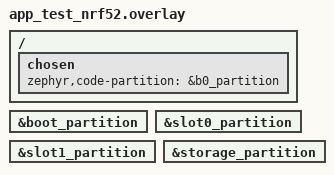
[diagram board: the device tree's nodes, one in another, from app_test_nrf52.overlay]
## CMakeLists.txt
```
#
# Copyright (c) 2019 Nordic Semiconductor ASA
#
# SPDX-License-Identifier: LicenseRef-Nordic-5-Clause
#

cmake_minimum_required(VERSION 3.20.0)

find_package(Zephyr REQUIRED HINTS $ENV{ZEPHYR_BASE})
project(bootloader)

zephyr_library_sources(src/main.c)

zephyr_compile_options("-include${CMAKE_CURRENT_LIST_DIR}/include//bl_partitions_dummy.h")
```

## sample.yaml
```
sample:
  name: Bootloader Sample
tests:
  sample.bootloader:
    sysbuild: true
    build_only: true
    integration_platforms:
      - nrf9160dk/nrf9160
      - nrf9161dk/nrf9161
      - nrf9151dk/nrf9151
      - nrf54l15dk/nrf54l15/cpuapp
    platform_allow:
      - nrf5340dk/nrf5340/cpuapp
      - nrf9160dk/nrf9160
      - nrf9161dk/nrf9161
      - nrf9151dk/nrf9151
      - nrf54l15dk/nrf54l15/cpuapp
    extra_args:
      - DTC_OVERLAY_FILE="app_test.overlay"
    tags:
      - ci_build
      - sysbuild
      - ci_samples_bootloader
```

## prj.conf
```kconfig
#
# Copyright (c) 2019 Nordic Semiconductor ASA
#
# SPDX-License-Identifier: LicenseRef-Nordic-5-Clause
#
CONFIG_IS_SECURE_BOOTLOADER=y
CONFIG_MULTITHREADING=n
CONFIG_GPIO=n
CONFIG_ARM_MPU=n
CONFIG_TICKLESS_KERNEL=n
CONFIG_ERRNO=n
CONFIG_FPROTECT=n
CONFIG_SECURE_BOOT_CRYPTO=y
CONFIG_LOG=y
CONFIG_LOG_MODE_MINIMAL=y
CONFIG_LOG_DEFAULT_LEVEL=0
CONFIG_SECURE_BOOT_VALIDATION=y
CONFIG_SECURE_BOOT_VALIDATION_LOG_LEVEL_INF=y
CONFIG_SECURE_BOOT_STORAGE=y
CONFIG_MAIN_STACK_SIZE=2048
CONFIG_TIMEOUT_64BIT=n

# Disable asserts because of false positive when writing to OTP.
CONFIG_ASSERT=n

# Avoid triggering IRQs from the RTC
CONFIG_NRF_RTC_TIMER=n
```

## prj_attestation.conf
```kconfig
# For TF-M to support attestation, NSIB must enable the mandatory IAT
# claim "implementation ID"
CONFIG_SB_IMPLEMENTATION_ID=y
```

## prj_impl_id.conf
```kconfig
# If Implementation Id is enabled in the parent image then it is supposed to be
# enabled in the b0 Child images as well
CONFIG_SB_IMPLEMENTATION_ID=y
```

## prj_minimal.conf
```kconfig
#
# Copyright (c) 2021 Nordic Semiconductor ASA
#
# SPDX-License-Identifier: LicenseRef-Nordic-5-Clause
#

CONFIG_B0_MIN_PARTITION_SIZE=y
CONFIG_FPROTECT=y
CONFIG_FW_INFO=y
CONFIG_IS_SECURE_BOOTLOADER=y
CONFIG_SECURE_BOOT_CRYPTO=y
CONFIG_SECURE_BOOT_STORAGE=y
CONFIG_SECURE_BOOT_VALIDATION=y
CONFIG_USE_DT_CODE_PARTITION=y

CONFIG_ARM_MPU=n
CONFIG_ASSERT=n
CONFIG_BOOT_BANNER=n
CONFIG_CONSOLE=n
CONFIG_ERRNO=n
CONFIG_GEN_IRQ_VECTOR_TABLE=n
CONFIG_GPIO=n
CONFIG_KERNEL_MEM_POOL=n
CONFIG_LOG=n
CONFIG_MULTITHREADING=n
CONFIG_NCS_SAMPLES_DEFAULTS=n
CONFIG_NRF_ENABLE_ICACHE=n
CONFIG_PRINTK=n
CONFIG_NCS_BOOT_BANNER=n
CONFIG_RESET_ON_FATAL_ERROR=n
CONFIG_LOG=n
CONFIG_SERIAL=n
CONFIG_SYS_CLOCK_EXISTS=n
CONFIG_TICKLESS_KERNEL=n
CONFIG_TIMEOUT_64BIT=n
CONFIG_UART_CONSOLE=n   # Set explicitly to 'n' to avoid Kconfig warning
CONFIG_USE_SEGGER_RTT=n

CONFIG_MAIN_STACK_SIZE=2048
```

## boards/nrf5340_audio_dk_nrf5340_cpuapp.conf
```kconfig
#
# Copyright (c) 2023 Nordic Semiconductor ASA
#
# SPDX-License-Identifier: LicenseRef-Nordic-5-Clause
#

# CC3xx is currently not used for nrf53
CONFIG_HW_CC3XX=n
CONFIG_NRF_CC3XX_PLATFORM=n
# nPM1100 is not used by the bootloader
CONFIG_REGULATOR_NPM1100=n
```

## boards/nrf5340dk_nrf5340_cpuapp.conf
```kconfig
#
# Copyright (c) 2020 Nordic Semiconductor ASA
#
# SPDX-License-Identifier: LicenseRef-BSD-5-Clause-Nordic
#

# CC3xx is currently not used for nrf53
CONFIG_HW_CC3XX=n
CONFIG_NRF_CC3XX_PLATFORM=n
```

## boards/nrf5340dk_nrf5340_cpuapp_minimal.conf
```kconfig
#
# Copyright (c) 2021 Nordic Semiconductor ASA
#
# SPDX-License-Identifier: LicenseRef-BSD-5-Clause-Nordic
#

# CC3xx is currently not used for nrf53
CONFIG_HW_CC3XX=n
CONFIG_NRF_CC3XX_PLATFORM=n
```

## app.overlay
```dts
/ {
	chosen {
		zephyr,code-partition = &b0_partition;
	};
};

b0_partition: &boot_partition {};
```

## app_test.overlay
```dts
/ {
	chosen {
		zephyr,code-partition = &b0_partition;
	};
};

b0_partition: &boot_partition {};

s0_partition: &slot0_partition {};

s1_partition: &slot1_partition {};
```

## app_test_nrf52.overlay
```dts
/ {
	chosen {
		zephyr,code-partition = &b0_partition;
	};
};

b0_partition: &boot_partition {};

s0_partition: &slot0_partition {};

s1_partition: &slot1_partition {};

provision_partition: &storage_partition {};

bl_storage: &provision_partition {};
```

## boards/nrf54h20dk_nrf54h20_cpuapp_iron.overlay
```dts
/*
 * Copyright (c) 2025 Nordic Semiconductor ASA
 *
 * SPDX-License-Identifier: LicenseRef-Nordic-5-Clause
 */

/ {
	chosen {
		zephyr,code-partition = &b0_partition;
	};
};
```

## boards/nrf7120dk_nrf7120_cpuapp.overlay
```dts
/*
 * Copyright (c) 2026 Nordic Semiconductor ASA
 *
 * SPDX-License-Identifier: LicenseRef-Nordic-5-Clause
 */

/*
 * NSIB partition setup for nrf7120 (no Partition Manager). Replaces the
 * sample's app.overlay, so it also defines b0_partition + the code-partition.
 * b0 is sized to 30K to fit the NSIB lock region.
 */

/ {
	chosen {
		zephyr,code-partition = &b0_partition;
	};
};

b0_partition: &boot_partition {
	reg = <0x0 0x7800>;
};
```

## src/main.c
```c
/*
 * Copyright (c) 2018 Nordic Semiconductor ASA
 *
 * SPDX-License-Identifier: LicenseRef-Nordic-5-Clause
 */

#include <zephyr/types.h>
#include <zephyr/kernel.h>
#include <zephyr/sys/printk.h>
#include <zephyr/storage/flash_map.h>
#include <fw_info.h>
#if defined(CONFIG_FPROTECT)
#include <fprotect.h>
#else
#if !defined(CONFIG_SOC_SERIES_NRF54L) && !defined(CONFIG_SOC_SERIES_NRF71)
#warning "FPROTECT not enabled, the bootloader will be unprotected."
#endif
#endif
#include <bl_storage.h>
#include <bl_boot.h>
#include <bl_validation.h>
#if defined(CONFIG_SOC_FLASH_NRF_UICR) || defined(CONFIG_SOC_FLASH_NRF_RRAM_UICR)
#include <zephyr/drivers/flash.h>
#elif defined(CONFIG_NRFX_NVMC)
#include <nrfx_nvmc.h>
#elif defined(CONFIG_NRFX_RRAMC)
#include <nrfx_rramc.h>
#elif defined(CONFIG_NRFX_MRAMC)
#include <nrfx_mramc.h>
#else
#error "No NRFX memory backend selected"
#endif
#ifdef CONFIG_SB_LCS_AWARE
#include <nrf_lcs/nrf_lcs.h>
#endif

/* When searching for fw_info, we get slot address as a base. The slot address,
 * equivalent to an offset of the partition the slot resides on, is the beginning
 * of a binary, which also includes non-executable header used by bootloaders.
 * The fw_info is offset, using linker script, within rom_start section
 * which is already, itself, offset by the header, if a header exists.
 * This means that fw_info is not placed at offset selected by
 * CONFIG_FW_INFO_OFFSET, in application configuration, but at the offset
 * equivalent to CONFIG_FW_INFO_OFFSET + CONFIG_ROM_START_OFFSET,
 * where CONFIG_ROM_START_OFFSET is also taken from application image.
 * We can not use CONFIG_ROM_START_OFFSET here, because here it is set for this
 * bootloader, and probably 0, so we have to rely on information set specific
 * for platform for Secure Bootloader via CONFIG_SB_IMAGE_BOOT_OFFSET,
 * or take it from Partition Manager padding.
 */
#if CONFIG_MCUBOOT_MCUBOOT_IMAGE_NUMBER == -1
#define APP_HEADER_SKIP	0
#else
#define APP_HEADER_SKIP	CONFIG_SB_IMAGE_BOOT_OFFSET
#endif

#if defined(CONFIG_FPROTECT)
/* Invoked from B0, FPROTECT will only protect B0 partition */
static const uint32_t b0_offset = PARTITION_OFFSET(b0_partition);
static const uint32_t b0_size = PARTITION_SIZE(b0_partition);
#endif

#if defined(CONFIG_HW_UNIQUE_KEY_LOAD)
#include <zephyr/init.h>
#include <hw_unique_key.h>

#define HUK_FLAG_OFFSET 0xFFC /* When this word is set, expect HUK to be written. */

/* huk_flag_addr is actually address in CPU address space, not offset within
 * flash device.
 */
static const uint32_t huk_flag_addr = PARTITION_ADDRESS(hw_unique_key_partition);

#if defined(CONFIG_NRFX_RRAMC) && !defined(CONFIG_SOC_FLASH_NRF_RRAM_UICR)
static bool rramc_configure(void)
{
	nrfx_rramc_config_t config = NRFX_RRAMC_DEFAULT_CONFIG(0);

	config.preload_timeout_enable = false;
	config.preload_timeout = 0;

	int err = nrfx_rramc_init(&config, NULL);

	if (err != 0 && err != -EALREADY) {
		return false;
	}

	return true;
}
#endif

int load_huk(void)
{
	if (!hw_unique_key_is_written(HUK_KEYSLOT_KDR)) {
		/* Directly reading flag via CPU address space */
		if (*(uint32_t *)huk_flag_addr == 0xFFFFFFFF) {
			printk("First boot, expecting app to write HUK.\n");
			/* Write done via NRFX API */
#if defined(CONFIG_SOC_FLASH_NRF_UICR) || defined(CONFIG_SOC_FLASH_NRF_RRAM_UICR)
			const uint32_t data = 0;
			const struct device *dev =
				DEVICE_DT_GET(DT_CHOSEN(zephyr_flash_controller));

			if (device_is_ready(dev)) {
				flash_write(dev, huk_flag_addr, &data, 4);
			} else {
				printk("Error: Unable to set Hardware Unique Key.\n");
				k_panic();
				return -1;
			}
#elif defined(CONFIG_NRFX_NVMC)
			nrfx_nvmc_word_write(huk_flag_addr, 0);
#elif defined(CONFIG_NRFX_RRAMC)
			if (rramc_configure()) {
				nrfx_rramc_word_write(huk_flag_addr, 0);
			} else {
				printk("Error: Unable to set Hardware Unique Key.\n");
				k_panic();
				return -1;
			}
#endif
			return 0;
		}
		printk("Error: Hardware Unique Key not present.\n");
		k_panic();
		return -1;

	}

	if (hw_unique_key_load_kdr() != HW_UNIQUE_KEY_SUCCESS) {
		printk("Error: Cannot load the Hardware Unique Key into the KDR.\n");
		k_panic();
		return -1;
	}

	return 0;
}

SYS_INIT(load_huk, PRE_KERNEL_2, 0);
#endif


static void validate_and_boot(const struct fw_info *fw_info, counter_t slot)
{
	printk("Attempting to boot slot %d.\r\n", slot);

	if (fw_info == NULL) {
		printk("No fw_info struct found.\r\n");
		return;
	}

	printk("Attempting to boot from address 0x%x.\r\n",
		fw_info->boot_address);

	if (!bl_validate_firmware_local(fw_info->address,
					fw_info)) {
		printk("Failed to validate, permanently invalidating!\r\n");
		fw_info_invalidate(fw_info);
		return;
	}

	printk("Firmware version %d\r\n", fw_info->version);

#ifdef CONFIG_SB_MONOTONIC_COUNTER_ROLLBACK_PROTECTION
	counter_t stored_version;

	int err = get_monotonic_version(&stored_version);

	if (err) {
		printk("Failed to read the monotonic counter!\r\n");
		return;
	}

	if (fw_info->version > stored_version) {
		int err = set_monotonic_version(fw_info->version, slot);

		if (err) {
			return;
		}
	}
#endif

	/*
	 * We can lock the keys and other resources now, as any failures
	 * in the bl_boot function are considered fatal and would prevent
	 * the alternate image from booting as well.
	 * Thus, we meet the criteria for calling bl_validate_housekeeping.
	 */
	bl_validate_housekeeping();

	bl_boot(fw_info);
}

#define BOOT_SLOT_0 0
#define BOOT_SLOT_1 1

int main(void)
{

#if defined(CONFIG_FPROTECT)
	int err = fprotect_area(b0_offset, b0_size);

	if (err) {
		printk("Failed to protect B0 flash, cancel startup.\r\n");
		return 0;
	}
#else
	printk("Fprotect disabled. No protection applied.\r\n");
#endif

#ifdef CONFIG_SB_LCS_AWARE
	printk("LCS-awareness enabled. Current LCS: %x\n\r", nrf_lcs_get());

	switch (nrf_lcs_get()) {
	case NRF_LCS_ASSEMBLY_AND_TEST:
	case NRF_LCS_PSA_ROT_PROVISIONING:
	case NRF_LCS_SECURED:
		/* Boot and update logic is allowed only in these three states. */
		break;

	default:
		printk("Device in an unbootable state: %x\n\r", nrf_lcs_get());
		return 0;
	}
#else
	printk("LCS-awareness disabled.\n\r");
#endif /* CONFIG_SB_LCS_AWARE */

	/* Get slot/partition start address and offset it with
	 * application header size.
	 */
	uint32_t s0_addr = s0_address_read() + APP_HEADER_SKIP;
	uint32_t s1_addr = s1_address_read() + APP_HEADER_SKIP;
	const struct fw_info *s0_info = fw_info_find(s0_addr);
	const struct fw_info *s1_info = fw_info_find(s1_addr);

	if (s0_info && s1_info) {
		if (s0_info->version >= s1_info->version) {
			validate_and_boot(s0_info, BOOT_SLOT_0);
			validate_and_boot(s1_info, BOOT_SLOT_1);
		} else {
			validate_and_boot(s1_info, BOOT_SLOT_1);
			validate_and_boot(s0_info, BOOT_SLOT_0);
		}
	} else if (s0_info) {
		validate_and_boot(s0_info, BOOT_SLOT_0);
	} else if (s1_info) {
		validate_and_boot(s1_info, BOOT_SLOT_1);
	}

	printk("No bootable image found. Aborting boot.\r\n");
	bl_validate_housekeeping();
	return 0;
}
```

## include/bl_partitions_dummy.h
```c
/*
 * Copyright (c) 2025 Nordic Semiconductor ASA
 *
 * SPDX-License-Identifier: LicenseRef-Nordic-5-Clause
 */

/* DUMMY FILE ONLY TO BE USED FOR TESTING */
#ifndef BL_PARTITIONS_H
#define BL_PARTITIONS_H

#define NSIB_B0_ADDRESS 0x8000
#define NSIB_B0_SIZE 0x1000
#define NSIB_PROVISION_ADDRESS 0x7000
#define NSIB_PROVISION_SIZE 0x1000

#define NSIB_S0_SIZE 0x10000
#define NSIB_S1_SIZE 0x10000

#endif /* BL_PARTITIONS_H */
```
